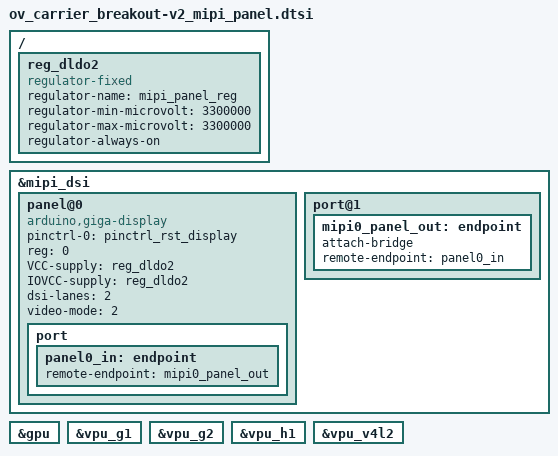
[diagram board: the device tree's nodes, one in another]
/ {
	reg_dldo2: reg_dldo2 {
		compatible = "regulator-fixed";
		regulator-name = "mipi_panel_reg";
		regulator-min-microvolt = <3300000>;
		regulator-max-microvolt = <3300000>;
		regulator-always-on;
	};
};

&mipi_dsi {
	status = "okay";

	panel@0 {
		pinctrl-names = "default";
		pinctrl-0 = <&pinctrl_rst_display>;
		compatible = "arduino,giga-display","sitronix,st7701";
		reg = <0>;
		VCC-supply = <&reg_dldo2>;
		IOVCC-supply = <&reg_dldo2>;
		dsi-lanes = <2>;
		video-mode = <2>;	/* 0: burst mode
							 * 1: non-burst mode with sync event
							 * 2: non-burst mode with sync pulse
							 */
		status = "okay";

		port {
			panel0_in: endpoint {
				remote-endpoint = <&mipi0_panel_out>;
			};
		};
	};

	port@1 {
		mipi0_panel_out: endpoint {
			attach-bridge;
			remote-endpoint = <&panel0_in>;
		};
	};
};

&gpu {
	status = "okay";
};

&vpu_g1 {
	status = "okay";
};

&vpu_g2 {
	status = "okay";
};

&vpu_h1 {
	status = "okay";
};

&vpu_v4l2 {
	status = "okay";
};
